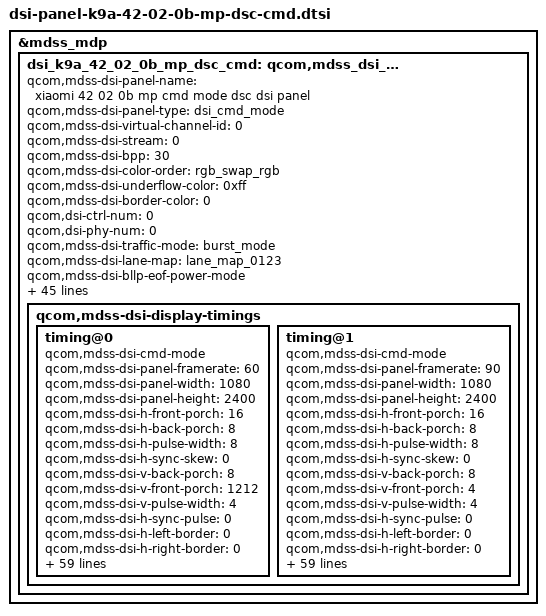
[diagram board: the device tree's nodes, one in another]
&mdss_mdp {
	dsi_k9a_42_02_0b_mp_dsc_cmd: qcom,mdss_dsi_k9a_42_02_0b_mp_dsc_cmd {
		qcom,mdss-dsi-panel-name = "xiaomi 42 02 0b mp cmd mode dsc dsi panel";
		qcom,mdss-dsi-panel-type = "dsi_cmd_mode";
		qcom,mdss-dsi-virtual-channel-id = <0>;
		qcom,mdss-dsi-stream = <0>;
		qcom,mdss-dsi-bpp = <30>;
		qcom,mdss-dsi-color-order = "rgb_swap_rgb";
		qcom,mdss-dsi-underflow-color = <0xff>;
		qcom,mdss-dsi-border-color = <0>;

		qcom,dsi-ctrl-num = <0>;
		qcom,dsi-phy-num = <0>;

		qcom,mdss-dsi-traffic-mode = "burst_mode";
		qcom,mdss-dsi-lane-map = "lane_map_0123";
		qcom,mdss-dsi-bllp-eof-power-mode;
		qcom,mdss-dsi-bllp-power-mode;
		qcom,mdss-dsi-lane-0-state;
		qcom,mdss-dsi-lane-1-state;
		qcom,mdss-dsi-lane-2-state;
		qcom,mdss-dsi-lane-3-state;
		qcom,mdss-dsi-dma-trigger = "trigger_sw";
		qcom,mdss-dsi-mdp-trigger = "none";
		qcom,mdss-dsi-reset-sequence =  <1 11>, <0 1>, <1 11>;
		qcom,mdss-pan-physical-width-dimension = <683>;
		qcom,mdss-pan-physical-height-dimension = <1517>;
		qcom,mdss-dsi-te-pin-select = <1>;
		qcom,mdss-dsi-wr-mem-start = <0x2c>;
		qcom,mdss-dsi-wr-mem-continue = <0x3c>;
		qcom,mdss-dsi-te-dcs-command = <1>;
		qcom,mdss-dsi-te-check-enable;
		qcom,mdss-dsi-te-using-te-pin;
		qcom,mdss-dsi-tx-eot-append;
		qcom,mdss-dsi-lp11-init;
		qcom,mdss-dsi-bl-inverted-dbv;
		qcom,bl-update-flag = "delay_until_first_frame";

		qcom,mdss-dsi-panel-hdr-enabled;
		qcom,mdss-dsi-panel-hdr-color-primaries = <14500 15500 32000 17000 15500 30000 8000 3000>;
		qcom,mdss-dsi-panel-peak-brightness = <4200000>;
		qcom,mdss-dsi-panel-blackness-level = <3230>;

		qcom,mdss-dsi-display-timings {
			timing@0{
				qcom,mdss-dsi-cmd-mode;
				qcom,mdss-dsi-panel-framerate = <60>;
				qcom,mdss-dsi-panel-width = <1080>;
				qcom,mdss-dsi-panel-height = <2400>;
				qcom,mdss-dsi-h-front-porch = <16>;
				qcom,mdss-dsi-h-back-porch = <8>;
				qcom,mdss-dsi-h-pulse-width = <8>;
				qcom,mdss-dsi-h-sync-skew = <0>;
				qcom,mdss-dsi-v-back-porch = <8>;
				qcom,mdss-dsi-v-front-porch = <1212>;
				qcom,mdss-dsi-v-pulse-width = <4>;
				qcom,mdss-dsi-h-sync-pulse = <0>;
				qcom,mdss-dsi-h-left-border = <0>;
				qcom,mdss-dsi-h-right-border = <0>;
				qcom,mdss-dsi-v-top-border = <0>;
				qcom,mdss-dsi-v-bottom-border = <0>;
				qcom,mdss-dsi-panel-clockrate = <652000000>;
				qcom,mdss-dsi-panel-jitter = <0x5 0x1>;
				qcom,mdss-mdp-transfer-time-us = <15700>;
				qcom,mdss-dsi-on-command = [
					/* VIDEO TRIM OFF*/
					39 00 00 00 00 00 06 F0 55 AA 52 08 01
					39 00 00 00 00 00 08 C3 00 01 94 D0 20 81 00
					39 01 00 00 00 00 03 C4 90 01
					/* Command Mode */
					39 00 00 00 00 00 06 F0 55 AA 52 08 00
					15 00 00 00 00 00 02 B2 98
					15 00 00 00 00 00 02 6F 02
					39 00 00 00 00 00 03 B2 0C 0C	/* 60Hz dimming speed: 12 frames*/
					/* ESD/MIPI Error Flag, Low when Error Happen */
					39 00 00 00 00 00 05 BE 0E 0B 14 13
					15 00 00 00 00 00 02 6F 05
					15 00 00 00 00 00 02 BE 8A
					15 00 00 00 00 00 02 C0 66
					15 00 00 00 00 00 02 6F 08
					15 01 00 00 00 00 02 B5 32
					/* Round Corner OFF */
					39 00 00 00 00 00 06 F0 55 AA 52 08 07
					39 01 00 00 00 00 03 C0 00 02
					39 00 00 00 00 00 06 F0 55 AA 52 08 01
					15 00 00 00 00 00 02 D1 07	// TP Hsync & Vsync Setting
					15 00 00 00 00 00 02 6F 02
					15 00 00 00 00 00 02 D1 06
					15 00 00 00 00 00 02 6F 05
					15 00 00 00 00 00 02 D1 06
					39 00 00 00 00 00 05 3B 00 10 00 30
					15 01 00 00 00 00 02 90 01	// VESA ON
					/* Choose VESA Edition */
					39 00 00 00 00 00 13 91
						AB 28 00 0C C2 00 03 1C 01 7E
						00 0F 08 BB 04 3D 10 F0	// DSC Setting
					15 00 00 00 00 00 02 03 01
					39 00 00 00 00 00 05 51 00 00 00 00	// Backlight
					15 00 00 00 00 00 02 53 20
					15 00 00 00 00 00 02 35 00	// TE ON
					39 00 00 00 00 00 05 2A 00 00 04 37
					39 00 00 00 00 00 05 2B 00 00 09 5F
					15 01 00 00 00 00 02 2F 01	// 60Hz
					/* Speed up code */
					39 00 00 00 00 00 06 F0 55 AA 52 08 00
					39 00 00 00 00 00 05 CA 12 00 92 02
					15 00 00 00 00 00 02 6F 02
					39 00 00 00 00 00 03 EC 80 10
					39 00 00 00 00 00 06 F0 55 AA 52 08 01
					39 00 00 00 00 00 03 CD 05 31
					15 00 00 00 00 00 02 6F 10
					15 01 00 00 00 00 02 D8 0C
					/* AOD optimization code */
					39 00 00 00 00 00 06 F0 55 AA 52 08 01
					15 00 00 00 00 00 02 6F 01
					39 00 00 00 00 00 04 D2 01 28 33
					/* Sleep Out */
					05 01 00 00 32 00 02 11 00
					/* Display On */
					05 01 00 00 10 00 02 29 00];
				qcom,mdss-dsi-off-command = [
					05 01 00 00 10 00 02 28 00
					05 01 00 00 78 00 02 10 00];
				qcom,mdss-dsi-on-command-state = "dsi_lp_mode";
				qcom,mdss-dsi-off-command-state = "dsi_lp_mode";

				qcom,mdss-dsi-timing-switch-command = [
					15 01 00 00 11 00 02 2F 01];
				qcom,mdss-dsi-timing-switch-command-state = "dsi_lp_mode";

				qcom,compression-mode = "dsc";
				qcom,mdss-dsc-version = <0x11>;
				qcom,mdss-dsc-scr-version = <0x0>;
				qcom,mdss-dsc-slice-height = <12>;
				qcom,mdss-dsc-slice-width = <1080>;
				qcom,mdss-dsc-slice-per-pkt = <1>;
				qcom,mdss-dsc-bit-per-component = <10>;
				qcom,mdss-dsc-bit-per-pixel = <8>;
				qcom,mdss-dsc-block-prediction-enable;
			};

			timing@1{
				qcom,mdss-dsi-cmd-mode;
				qcom,mdss-dsi-panel-framerate = <90>;
				qcom,mdss-dsi-panel-width = <1080>;
				qcom,mdss-dsi-panel-height = <2400>;
				qcom,mdss-dsi-h-front-porch = <16>;
				qcom,mdss-dsi-h-back-porch = <8>;
				qcom,mdss-dsi-h-pulse-width = <8>;
				qcom,mdss-dsi-h-sync-skew = <0>;
				qcom,mdss-dsi-v-back-porch = <8>;
				qcom,mdss-dsi-v-front-porch = <4>;
				qcom,mdss-dsi-v-pulse-width = <4>;
				qcom,mdss-dsi-h-sync-pulse = <0>;
				qcom,mdss-dsi-h-left-border = <0>;
				qcom,mdss-dsi-h-right-border = <0>;
				qcom,mdss-dsi-v-top-border = <0>;
				qcom,mdss-dsi-v-bottom-border = <0>;
				qcom,mdss-dsi-panel-clockrate = <652000000>;
				qcom,mdss-dsi-panel-jitter = <0x5 0x1>;
				qcom,mdss-mdp-transfer-time-us = <9500>;
				qcom,mdss-dsi-on-command = [
					/* VIDEO TRIM OFF*/
					39 00 00 00 00 00 06 F0 55 AA 52 08 01
					39 00 00 00 00 00 08 C3 00 01 94 D0 20 81 00
					39 01 00 00 00 00 03 C4 90 01
					/* Command Mode */
					39 00 00 00 00 00 06 F0 55 AA 52 08 00
					15 00 00 00 00 00 02 B2 98
					15 00 00 00 00 00 02 6F 02
					39 00 00 00 00 00 03 B2 12 12	/* 90Hz dimming speed: 18 frames*/
					/* ESD/MIPI Error Flag, Low when Error Happen */
					39 00 00 00 00 00 05 BE 0E 0B 14 13
					15 00 00 00 00 00 02 6F 05
					15 00 00 00 00 00 02 BE 8A
					15 00 00 00 00 00 02 C0 66
					15 00 00 00 00 00 02 6F 08
					15 01 00 00 00 00 02 B5 32
					/* Round Corner OFF */
					39 00 00 00 00 00 06 F0 55 AA 52 08 07
					39 01 00 00 00 00 03 C0 00 02
					39 00 00 00 00 00 06 F0 55 AA 52 08 01
					15 00 00 00 00 00 02 D1 07	// TP Hsync & Vsync Setting
					15 00 00 00 00 00 02 6F 02
					15 00 00 00 00 00 02 D1 06
					15 00 00 00 00 00 02 6F 05
					15 00 00 00 00 00 02 D1 06
					39 00 00 00 00 00 05 3B 00 10 00 30
					15 01 00 00 00 00 02 90 01	// VESA ON
					/* Choose VESA Edition */
					39 00 00 00 00 00 13 91
						AB 28 00 0C C2 00 03 1C 01 7E
						00 0F 08 BB 04 3D 10 F0	// DSC Setting
					15 00 00 00 00 00 02 03 01
					39 00 00 00 00 00 05 51 00 00 00 00	// Backlight
					15 00 00 00 00 00 02 53 20
					15 00 00 00 00 00 02 35 00	// TE ON
					39 00 00 00 00 00 05 2A 00 00 04 37
					39 00 00 00 00 00 05 2B 00 00 09 5F
					15 01 00 00 00 00 02 2F 02	// 90Hz
					/* Speed up code */
					39 00 00 00 00 00 06 F0 55 AA 52 08 00
					39 00 00 00 00 00 05 CA 12 00 92 02
					15 00 00 00 00 00 02 6F 02
					39 00 00 00 00 00 03 EC 80 10
					39 00 00 00 00 00 06 F0 55 AA 52 08 01
					39 00 00 00 00 00 03 CD 05 31
					15 00 00 00 00 00 02 6F 10
					15 00 00 00 00 00 02 D8 0C
					/* AOD optimization code */
					39 00 00 00 00 00 06 F0 55 AA 52 08 01
					15 00 00 00 00 00 02 6F 01
					39 00 00 00 00 00 04 D2 01 28 33
					/* Sleep Out */
					05 01 00 00 32 00 02 11 00
					/* Display On */
					05 01 00 00 10 00 02 29 00];
				qcom,mdss-dsi-off-command = [
					05 01 00 00 10 00 02 28 00
					05 01 00 00 78 00 02 10 00];
				qcom,mdss-dsi-on-command-state = "dsi_lp_mode";
				qcom,mdss-dsi-off-command-state = "dsi_lp_mode";

				qcom,mdss-dsi-timing-switch-command = [
					15 01 00 00 11 00 02 2F 02];
				qcom,mdss-dsi-timing-switch-command-state = "dsi_lp_mode";

				qcom,compression-mode = "dsc";
				qcom,mdss-dsc-version = <0x11>;
				qcom,mdss-dsc-scr-version = <0x0>;
				qcom,mdss-dsc-slice-height = <12>;
				qcom,mdss-dsc-slice-width = <1080>;
				qcom,mdss-dsc-slice-per-pkt = <1>;
				qcom,mdss-dsc-bit-per-component = <10>;
				qcom,mdss-dsc-bit-per-pixel = <8>;
				qcom,mdss-dsc-block-prediction-enable;
			};
		};
	};
};

&dsi_k9a_42_02_0b_mp_dsc_cmd {
	qcom,mdss-dsi-bl-xiaomi-k9a-36-flag;
	//qcom,mdss-dsi-te-using-wd;

	/* HBM OFF param*/
	qcom,dispparam-f4-51-ctrl-flag;
	qcom,mdss-dsi-panel-hbm-off-51-index = <1>;

	/* IRQF_ONESHOT | IRQF_TRIGGER_FALLING */
	qcom,esd-err-irq-gpio = <&tlmm 32 0x2002>;

	qcom,esd-check-enabled;
	qcom,mdss-dsi-panel-status-check-mode = "reg_read";
	qcom,mdss-dsi-panel-status-offset-command = [
		39 01 00 00 00 00 05 FF AA 55 A5 81
		15 01 00 00 00 00 02 6F 0F];
	qcom,mdss-dsi-panel-status-command = [06 01 00 00 00 00 01 FA];
	qcom,mdss-dsi-panel-status-command-state = "dsi_lp_mode";
	qcom,mdss-dsi-panel-status-offset-command-state = "dsi_lp_mode";
	qcom,mdss-dsi-panel-status-value = <0x00>;
	qcom,mdss-dsi-panel-status-read-length = <1>;

	/* Support FPS switch */
	qcom,mdss-dsi-panel-mode-switch;

	/* Support display feature command */
	qcom,dispparam-enabled;
	qcom,mdss-panel-on-dimming-delay = <120>;
	qcom,mdss-dsi-display-timings {
		timing@0{
			qcom,mdss-dsi-dispparam-hbm-on-command = [
				15 01 00 00 01 00 02 53 28
				39 01 00 00 00 00 05 51 0F FF 00 00];
			qcom,mdss-dsi-dispparam-hbm-on-command-state = "dsi_lp_mode";
			qcom,mdss-dsi-dispparam-hbm-off-command = [
				15 01 00 00 01 00 02 53 28
				39 01 00 00 00 00 05 51 07 FF 00 00];
			qcom,mdss-dsi-dispparam-hbm-off-command-state = "dsi_lp_mode";

			qcom,mdss-dsi-dispparam-dimmingon-command = [15 01 00 00 00 00 02 53 28];
			qcom,mdss-dsi-dispparam-dimmingon-command-state = "dsi_lp_mode";
			qcom,mdss-dsi-dispparam-dimmingoff-command = [15 01 00 00 00 00 02 53 20];
			qcom,mdss-dsi-dispparam-dimmingoff-command-state = "dsi_lp_mode";

			qcom,mdss-dsi-dispparam-flat-mode-on-command =[
				39 01 00 00 00 00 06 F0 55 AA 52 08 08
				15 01 00 00 00 00 02 B9 01];
			qcom,mdss-dsi-dispparam-flat-mode-on-command-state = "dsi_lp_mode";
			qcom,mdss-dsi-dispparam-flat-mode-off-command =[
				39 01 00 00 00 00 06 F0 55 AA 52 08 08
				15 01 00 00 00 00 02 B9 00];
			qcom,mdss-dsi-dispparam-flat-mode-off-command-state = "dsi_lp_mode";

			qcom,mdss-dsi-doze-hbm-command = [
				15 01 00 00 00 00 02 2F 01
				39 01 00 00 00 00 05 51 00 00 0F FF
				39 01 00 00 00 00 06 F0 55 AA 52 08 00
				15 01 00 00 00 00 02 B2 08
				05 01 00 00 14 00 01 39
				15 01 00 00 00 00 02 65 01];
			qcom,mdss-dsi-doze-hbm-command-state = "dsi_lp_mode";
			qcom,mdss-dsi-doze-lbm-command = [
				15 01 00 00 00 00 02 2F 01
				39 01 00 00 00 00 05 51 00 00 01 55
				39 01 00 00 00 00 06 F0 55 AA 52 08 00
				15 01 00 00 00 00 02 B2 08
				05 01 00 00 14 00 01 39
				15 01 00 00 00 00 02 65 01];
			qcom,mdss-dsi-doze-lbm-command-state = "dsi_lp_mode";
			qcom,mdss-dsi-nolp-command = [
				39 01 00 00 00 00 06 F0 55 AA 52 08 00
				15 01 00 00 00 00 02 B2 98
				15 01 00 00 00 00 02 65 00
				05 01 00 00 00 00 01 38
				15 01 00 00 00 00 02 2F 01];
			qcom,mdss-dsi-nolp-command-state = "dsi_lp_mode";
		};

		timing@1{
			qcom,mdss-dsi-dispparam-hbm-on-command = [
				15 01 00 00 00 00 02 53 28
				39 01 00 00 00 00 05 51 0F FF 00 00];
			qcom,mdss-dsi-dispparam-hbm-on-command-state = "dsi_lp_mode";
			qcom,mdss-dsi-dispparam-hbm-off-command = [
				15 01 00 00 00 00 02 53 28
				39 01 00 00 00 00 05 51 07 FF 00 00];
			qcom,mdss-dsi-dispparam-hbm-off-command-state = "dsi_lp_mode";

			qcom,mdss-dsi-dispparam-dimmingon-command = [15 01 00 00 00 00 02 53 28];
			qcom,mdss-dsi-dispparam-dimmingon-command-state = "dsi_lp_mode";
			qcom,mdss-dsi-dispparam-dimmingoff-command = [15 01 00 00 00 00 02 53 20];
			qcom,mdss-dsi-dispparam-dimmingoff-command-state = "dsi_lp_mode";

			qcom,mdss-dsi-dispparam-flat-mode-on-command =[
				39 01 00 00 00 00 06 F0 55 AA 52 08 08
				15 01 00 00 00 00 02 B9 01];
			qcom,mdss-dsi-dispparam-flat-mode-on-command-state = "dsi_lp_mode";
			qcom,mdss-dsi-dispparam-flat-mode-off-command =[
				39 01 00 00 00 00 06 F0 55 AA 52 08 08
				15 01 00 00 00 00 02 B9 00];
			qcom,mdss-dsi-dispparam-flat-mode-off-command-state = "dsi_lp_mode";

			qcom,mdss-dsi-doze-hbm-command = [
				15 01 00 00 00 00 02 2F 01
				39 01 00 00 00 00 05 51 00 00 0F FF
				39 01 00 00 00 00 06 F0 55 AA 52 08 00
				15 01 00 00 00 00 02 B2 08
				05 01 00 00 14 00 01 39
				15 01 00 00 00 00 02 65 01];
			qcom,mdss-dsi-doze-hbm-command-state = "dsi_lp_mode";
			qcom,mdss-dsi-doze-lbm-command = [
				15 01 00 00 00 00 02 2F 01
				39 01 00 00 00 00 05 51 00 00 01 55
				39 01 00 00 00 00 06 F0 55 AA 52 08 00
				15 01 00 00 00 00 02 B2 08
				05 01 00 00 14 00 01 39
				15 01 00 00 00 00 02 65 01];
			qcom,mdss-dsi-doze-lbm-command-state = "dsi_lp_mode";
			qcom,mdss-dsi-nolp-command = [
				39 01 00 00 00 00 06 F0 55 AA 52 08 00
				15 01 00 00 00 00 02 B2 98
				15 01 00 00 00 00 02 65 00
				05 01 00 00 00 00 01 38
				15 01 00 00 00 00 02 2F 02];
			qcom,mdss-dsi-nolp-command-state = "dsi_lp_mode";
		};
	};
};
